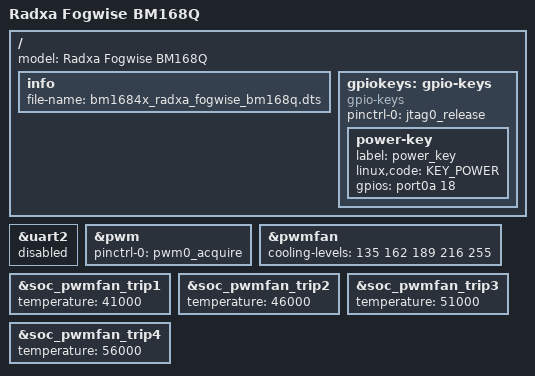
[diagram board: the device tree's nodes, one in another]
#include "bm1684x_radxa_aicore.dtsi"
#include <dt-bindings/input/input.h>

/ {
	model = "Radxa Fogwise BM168Q";
	/delete-node/ pka@58008000;
	/delete-node/ clp890@50018000;
	info {
		file-name = "bm1684x_radxa_fogwise_bm168q.dts";
	};

	gpiokeys: gpio-keys {
		compatible = "gpio-keys";
		pinctrl-names = "default";
		pinctrl-0 = <&jtag0_release>;

		power-key {
			label = "power_key";
			linux,code = <KEY_POWER>;
			gpios = <&port0a 18 GPIO_ACTIVE_HIGH>;
		};
	};
};

&uart2 {
	status = "disabled";
};

&pwm{
	pinctrl-names = "default";
	pinctrl-0 = <&pwm0_acquire>;
};

&pwmfan {
	status = "okay";
	cooling-levels = <135 162 189 216 255>;
};

&soc_pwmfan_trip1 {
	temperature = <41000>; /* millicelsius */
};

&soc_pwmfan_trip2 {
	temperature = <46000>; /* millicelsius */
};

&soc_pwmfan_trip3 {
	temperature = <51000>; /* millicelsius */
};

&soc_pwmfan_trip4 {
	temperature = <56000>; /* millicelsius */
};
